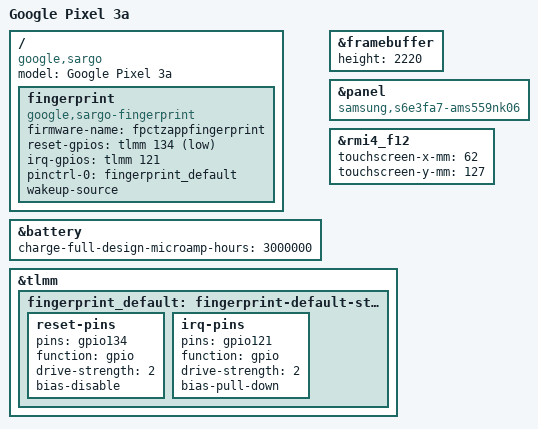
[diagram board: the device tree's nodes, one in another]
// SPDX-License-Identifier: GPL-2.0-only
/*
 * Device tree for Google Pixel 3a (non-XL).
 *
 * Copyright (c) Richard Acayan. All rights reserved.
 */

/dts-v1/;

#include "sdm670-google-common.dtsi"

/ {
	model = "Google Pixel 3a";
	compatible = "google,sargo", "qcom,sdm670";

	fingerprint {
		compatible = "google,sargo-fingerprint", "fpc,fpc1020";
		firmware-name = "fpctzappfingerprint";
		reset-gpios = <&tlmm 134 GPIO_ACTIVE_LOW>;
		irq-gpios = <&tlmm 121 GPIO_ACTIVE_HIGH>;
		pinctrl-names = "default";
		pinctrl-0 = <&fingerprint_default>;
		wakeup-source;
	};
};

&battery {
	charge-full-design-microamp-hours = <3000000>;
};

&framebuffer {
	height = <2220>;
};

&panel {
	compatible = "samsung,s6e3fa7-ams559nk06";
};

&rmi4_f12 {
	touchscreen-x-mm = <62>;
	touchscreen-y-mm = <127>;
};

&tlmm {
	fingerprint_default: fingerprint-default-state {
		reset-pins {
			pins = "gpio134";
			function = "gpio";
			drive-strength = <2>;
			bias-disable;
		};

		irq-pins {
			pins = "gpio121";
			function = "gpio";
			drive-strength = <2>;
			bias-pull-down;
		};
	};
};
